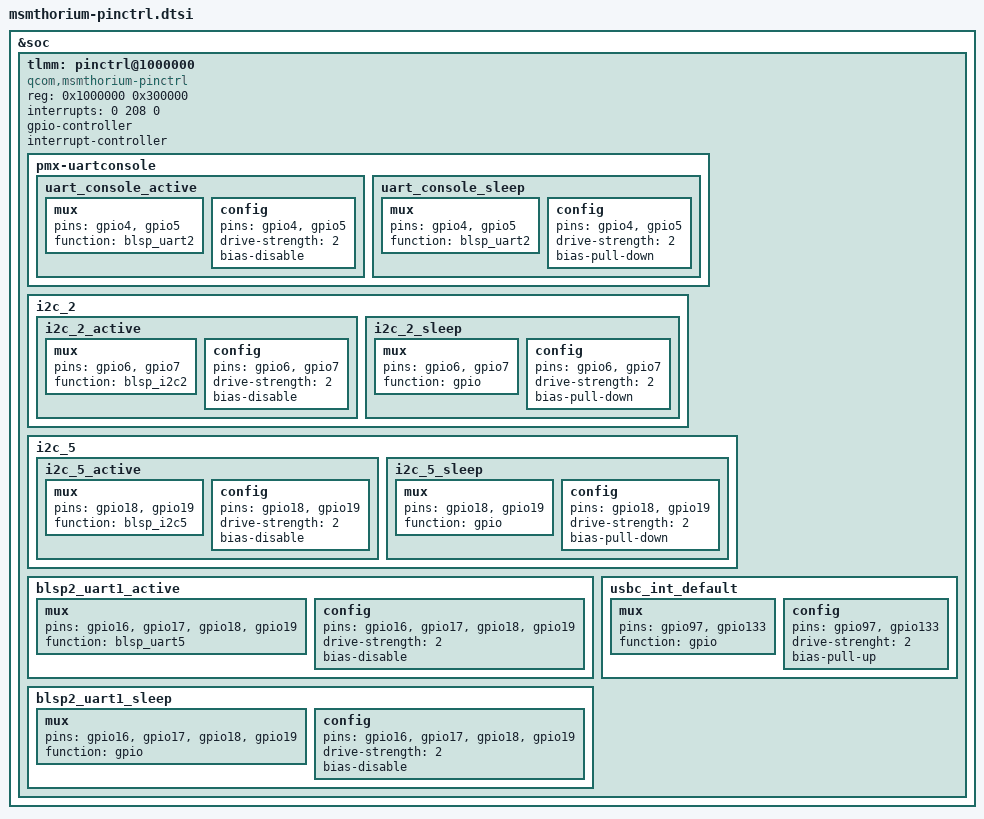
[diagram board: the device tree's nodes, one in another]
/*
 * Copyright (c) 2015, The Linux Foundation. All rights reserved.
 *
 * This program is free software; you can redistribute it and/or modify
 * it under the terms of the GNU General Public License version 2 and
 * only version 2 as published by the Free Software Foundation.
 *
 * This program is distributed in the hope that it will be useful,
 * but WITHOUT ANY WARRANTY; without even the implied warranty of
 * MERCHANTABILITY or FITNESS FOR A PARTICULAR PURPOSE.  See the
 * GNU General Public License for more details.
 */

&soc {
	tlmm: pinctrl@1000000 {
		compatible = "qcom,msmthorium-pinctrl";
		reg = <0x1000000 0x300000>;
		interrupts = <0 208 0>;
		gpio-controller;
		#gpio-cells = <2>;
		interrupt-controller;
		#interrupt-cells = <2>;

		pmx-uartconsole {
			uart_console_active: uart_console_active {
				mux {
					pins = "gpio4", "gpio5";
					function = "blsp_uart2";
				};

				config {
					pins = "gpio4", "gpio5";
					drive-strength = <2>;
					bias-disable;
				};
			};

			uart_console_sleep: uart_console_sleep {
				mux {
					pins = "gpio4", "gpio5";
					function = "blsp_uart2";
				};

				config {
					pins = "gpio4", "gpio5";
					drive-strength = <2>;
					bias-pull-down;
				};
			};

		};

		i2c_2 {
			i2c_2_active: i2c_2_active {
				/* active state */
				mux {
					pins = "gpio6", "gpio7";
					function = "blsp_i2c2";
				};

				config {
					pins = "gpio6", "gpio7";
					drive-strength = <2>;
					bias-disable;
				};
			};

			i2c_2_sleep: i2c_2_sleep {
				/* suspended state */
				mux {
					pins = "gpio6", "gpio7";
					function = "gpio";
				};

				config {
					pins = "gpio6", "gpio7";
					drive-strength = <2>;
					bias-pull-down;
				};
			};
		};

		i2c_5 {
			i2c_5_active: i2c_5_active {
				/* active state */
				mux {
					pins = "gpio18", "gpio19";
					function = "blsp_i2c5";
				};

				config {
					pins = "gpio18", "gpio19";
					drive-strength = <2>;
					bias-disable;
				};
			};

			i2c_5_sleep: i2c_5_sleep {
				/* suspended state */
				mux {
					pins = "gpio18", "gpio19";
					function = "gpio";
				};

				config {
					pins = "gpio18", "gpio19";
					drive-strength = <2>;
					bias-pull-down;
				};
			};
		};

		blsp2_uart1_active: blsp2_uart1_active {
			mux {
				pins = "gpio16", "gpio17", "gpio18", "gpio19";
				function = "blsp_uart5";
			};

			config {
				pins = "gpio16", "gpio17", "gpio18", "gpio19";
				drive-strength = <2>;
				bias-disable;
			};
		};

		blsp2_uart1_sleep: blsp2_uart1_sleep {
			mux {
				pins = "gpio16", "gpio17", "gpio18", "gpio19";
				function = "gpio";
			};

			config {
				pins = "gpio16", "gpio17", "gpio18", "gpio19";
				drive-strength = <2>;
				bias-disable;
			};
		};

		usbc_int_default: usbc_int_default {
			mux {
				pins = "gpio97", "gpio133";
				function = "gpio";
			};

			config {
				pins = "gpio97", "gpio133";
				drive-strenght = <2>;
				bias-pull-up;
			};
		};
	};
};
